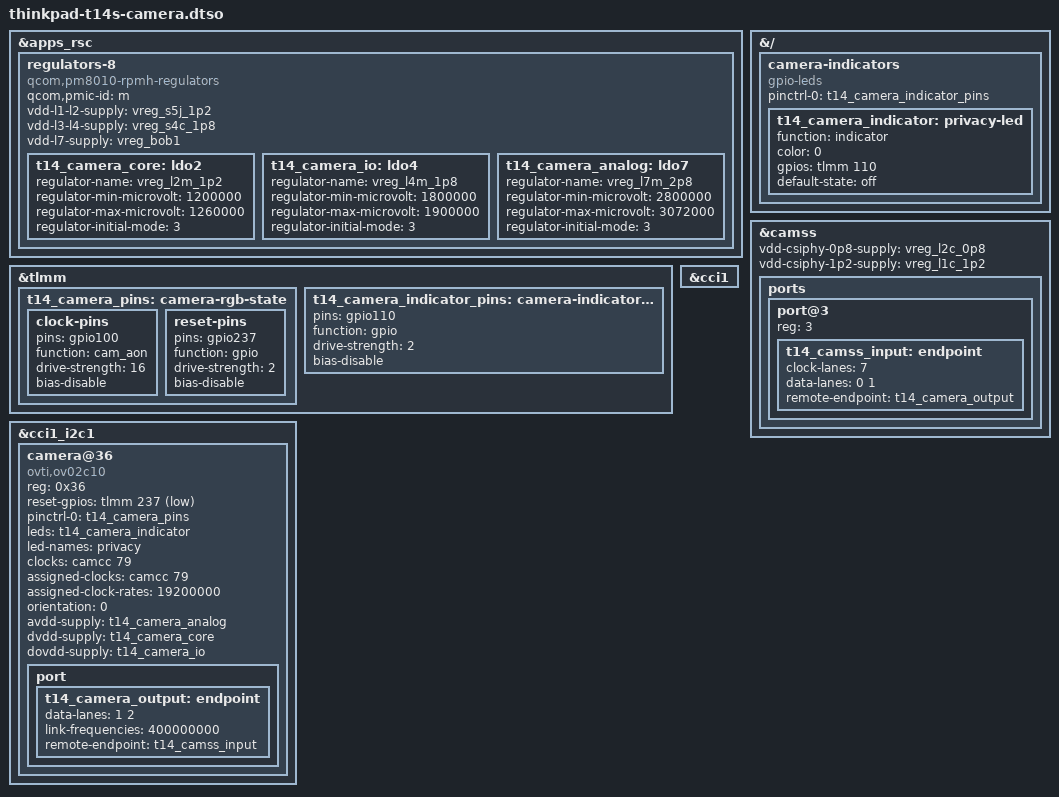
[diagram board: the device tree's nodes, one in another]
// SPDX-License-Identifier: GPL-2.0-only
/dts-v1/;
/plugin/;

// Camera wiring: Ubuntu resolute, commit 68d75f0820869e33326712a9547550961795eaaf.
&apps_rsc {
  regulators-8 {
    compatible = "qcom,pm8010-rpmh-regulators";
    qcom,pmic-id = "m";
    vdd-l1-l2-supply = <&vreg_s5j_1p2>;
    vdd-l3-l4-supply = <&vreg_s4c_1p8>;
    vdd-l7-supply = <&vreg_bob1>;

    t14_camera_core: ldo2 {
      regulator-name = "vreg_l2m_1p2";
      regulator-min-microvolt = <1200000>;
      regulator-max-microvolt = <1260000>;
      regulator-initial-mode = <3>;
    };

    t14_camera_io: ldo4 {
      regulator-name = "vreg_l4m_1p8";
      regulator-min-microvolt = <1800000>;
      regulator-max-microvolt = <1900000>;
      regulator-initial-mode = <3>;
    };

    t14_camera_analog: ldo7 {
      regulator-name = "vreg_l7m_2p8";
      regulator-min-microvolt = <2800000>;
      regulator-max-microvolt = <3072000>;
      regulator-initial-mode = <3>;
    };
  };
};

&tlmm {
  t14_camera_pins: camera-rgb-state {
    clock-pins {
      pins = "gpio100";
      function = "cam_aon";
      drive-strength = <16>;
      bias-disable;
    };

    reset-pins {
      pins = "gpio237";
      function = "gpio";
      drive-strength = <2>;
      bias-disable;
    };
  };

  t14_camera_indicator_pins: camera-indicator-state {
    pins = "gpio110";
    function = "gpio";
    drive-strength = <2>;
    bias-disable;
  };
};

&{/} {
  camera-indicators {
    compatible = "gpio-leds";
    pinctrl-0 = <&t14_camera_indicator_pins>;
    pinctrl-names = "default";

    t14_camera_indicator: privacy-led {
      function = "indicator";
      color = <0>;
      gpios = <&tlmm 110 0>;
      default-state = "off";
    };
  };
};

&camss {
  // This kernel exposes the PHY supplies on CAMSS, not a separate PHY node.
  vdd-csiphy-0p8-supply = <&vreg_l2c_0p8>;
  vdd-csiphy-1p2-supply = <&vreg_l1c_1p2>;
  status = "okay";

  ports {
    #address-cells = <1>;
    #size-cells = <0>;

    port@3 {
      reg = <3>;

      t14_camss_input: endpoint {
        clock-lanes = <7>;
        data-lanes = <0 1>;
        remote-endpoint = <&t14_camera_output>;
      };
    };
  };
};

&cci1 {
  status = "okay";
};

&cci1_i2c1 {
  #address-cells = <1>;
  #size-cells = <0>;

  camera@36 {
    compatible = "ovti,ov02c10";
    reg = <0x36>;
    reset-gpios = <&tlmm 237 1>;
    pinctrl-0 = <&t14_camera_pins>;
    pinctrl-names = "default";
    leds = <&t14_camera_indicator>;
    led-names = "privacy";
    clocks = <&camcc 79>;
    assigned-clocks = <&camcc 79>;
    assigned-clock-rates = <19200000>;
    orientation = <0>;
    avdd-supply = <&t14_camera_analog>;
    dvdd-supply = <&t14_camera_core>;
    dovdd-supply = <&t14_camera_io>;

    port {
      t14_camera_output: endpoint {
        data-lanes = <1 2>;
        link-frequencies = /bits/ 64 <400000000>;
        remote-endpoint = <&t14_camss_input>;
      };
    };
  };
};
